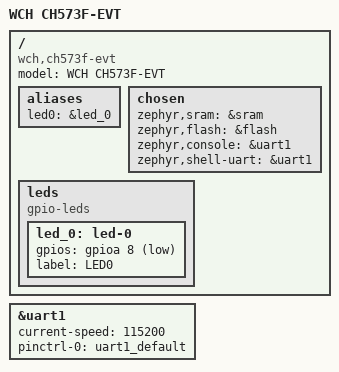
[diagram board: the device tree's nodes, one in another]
/*
 * Copyright (c) 2023 Chen Xingyu <hi@xingrz.me>
 * SPDX-License-Identifier: Apache-2.0
 */

/dts-v1/;

#include <zephyr/dt-bindings/gpio/gpio.h>
#include <wch/ch57x/ch573f.dtsi>
#include <wch/ch57x/ch573f-pinctrl.dtsi>

/ {
	model = "WCH CH573F-EVT";
	compatible = "wch,ch573f-evt";

	aliases {
		led0 = &led_0;
	};

	chosen {
		zephyr,sram = &sram;
		zephyr,flash = &flash;
		zephyr,console = &uart1;
		zephyr,shell-uart = &uart1;
	};

	leds {
		compatible = "gpio-leds";

		led_0: led-0 {
			gpios = <&gpioa 8 GPIO_ACTIVE_LOW>;
			label = "LED0";
		};
	};
};

&uart1 {
	status = "okay";
	current-speed = <115200>;
	pinctrl-0 = <&uart1_default>;
	pinctrl-names = "default";
};
